# ATA5700M322 device description
Architecture: AVR8; Family: megaAVR
Registers are 8-bit, access not given, no defined reset value unless marked. A register's access mark holds for its fields unless they carry their own. Offsets are from the block's base; [hi:lo] are bit positions; {n}, {i} and the like mark numbered series.

## LF_RSSI
Instances: LF_RSSI 0x00
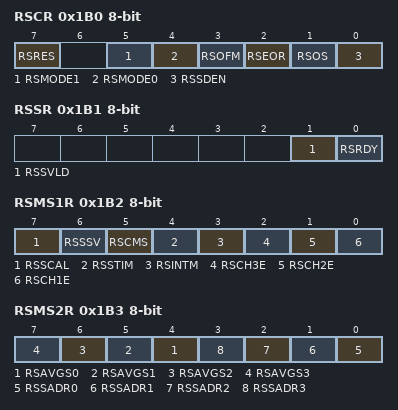
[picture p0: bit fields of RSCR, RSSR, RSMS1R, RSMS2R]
0x1B0 RSCR — RSSI Control Register
  [7] RSRES — RSSI Reset Bit
  [5] RSMODE1 — RSSI Mode Bit 1
  [4] RSMODE0 — RSSI Mode Bit 0
  [3] RSOFM — RSSI Operation Flag Mask Bit
  [2] RSEOR — RSSI End Operation Request Bit
  [1] RSOS — RSSI Operation Start Bit
  [0] RSSDEN — RSSI Sign Detection Enable Bit
0x1B1 RSSR — RSSI Status Register
  [1] RSSVLD — RSSI Sample Valid Bit
  [0] RSRDY — RSSI Ready Bit
0x1B2 RSMS1R — RSSI Measurement Setting 1 Register
  [7] RSSCAL — RSSI Set Calibration Bit
  [6] RSSSV — RSSI Show Sample Value Bit
  [5] RSCMS — RSSI Current Mode Select Bit
  [4] RSSTIM — RSSI Stimulus Bit
  [3] RSINTM — RSSI internal Measurement Bit
  [2] RSCH3E — RSSI Channel 3 Enable Bit
  [1] RSCH2E — RSSI Channel 2 Enable Bit
  [0] RSCH1E — RSSI Channel 1 Enable Bit
0x1B3 RSMS2R — RSSI Measurement Setting 2 Register
  [n+4] RSAVGS{n} (n=0..3) — RSSI Average Select Bit {n}
  [n] RSSADR{n} (n=0..3) — RSSI Sample Address Bit {n}
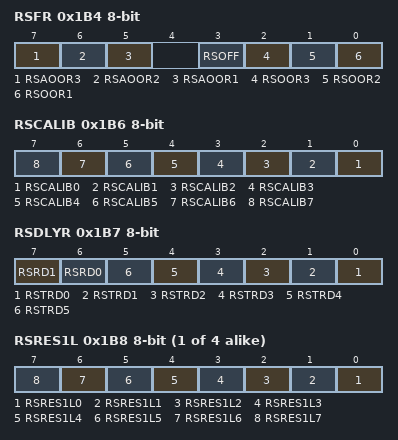
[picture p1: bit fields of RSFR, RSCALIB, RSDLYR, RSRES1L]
0x1B4 RSFR — RSSI Flag Register
  [7] RSAOOR3 — RSSI Averaging Out of Range Channel 3 Bit
  [6] RSAOOR2 — RSSI Averaging Out of Range Channel 2 Bit
  [5] RSAOOR1 — RSSI Averaging Out of Range Channel 1 Bit
  [3] RSOFF — RSSI Operation Finish Flag Bit
  [2] RSOOR3 — RSSI Out of Range Channel 3 Bit
  [1] RSOOR2 — RSSI Out of Range Channel 2 Bit
  [0] RSOOR1 — RSSI Out of Range Channel 1 Bit
0x1B6 RSCALIB — RSSI Calibration Register
  [n] RSCALIB{n} (n=0..7) — RSSI Calibration Bit {n}
0x1B7 RSDLYR — RSSI Delay Register
  [7] RSRD1 — RSSI Range Delay Bit 1
  [6] RSRD0 — RSSI Range Delay Bit 0
  [n] RSTRD{n} (n=0..5) — RSSI Tracking Delay Bit {n}
{0x1B6+2i} RSRES{i}L (i=1..4) — RSSI Result {i} Low Byte Register
  [n] RSRES{i}L{n} (n=0..7) — RSSI Result {i} Low Byte Bit {n}
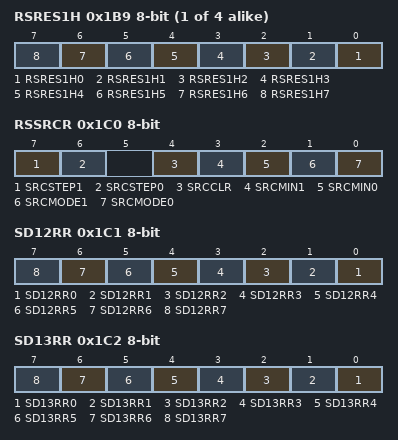
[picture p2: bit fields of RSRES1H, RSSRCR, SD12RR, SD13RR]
{0x1B7+2i} RSRES{i}H (i=1..4) — RSSI Result {i} High Byte Register
  [n] RSRES{i}H{n} (n=0..7) — RSSI Result {i} High Byte Bit {n}
0x1C0 RSSRCR — RSSI SRC Calibration Register
  [7] SRCSTEP1 — RSSI SRC Step Bit 1
  [6] SRCSTEP0 — RSSI SRC Step Bit 0
  [4] SRCCLR — RSSI SRC Clear Bit
  [3] SRCMIN1 — RSSI SRC Minimum Value Bit 1
  [2] SRCMIN0 — RSSI SRC Minimum Value Bit 0
  [1] SRCMODE1 — RSSI SRC Calibration Mode Bit 1
  [0] SRCMODE0 — RSSI SRC Calibration Mode Bit 0
0x1C1 SD12RR — Sign Detection Channel 1 vs 2 Result Register
  [n] SD12RR{n} (n=0..7) — Sign Detection Channel 1 vs 2 Result Bit {n}
0x1C2 SD13RR — Sign Detection Channel 1 vs 3 Result Register
  [n] SD13RR{n} (n=0..7) — Sign Detection Channel 1 vs 3 Result Bit {n}
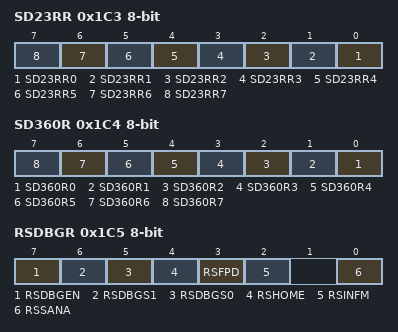
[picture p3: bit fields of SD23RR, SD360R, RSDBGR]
0x1C3 SD23RR — Sign Detection Channel 2 vs 3 Result Register
  [n] SD23RR{n} (n=0..7) — Sign Detection Channel 2 vs 3 Result Bit {n}
0x1C4 SD360R — Sign Detection 360 Degree Result Register
  [n] SD360R{n} (n=0..7) — Sign Detection 360 Degree Result Bit {n}
0x1C5 RSDBGR — RSSI Debug Register
  [7] RSDBGEN — RSSI Debug Enable Bit
  [6] RSDBGS1 — RSSI Debug Select Bit 1
  [5] RSDBGS0 — RSSI Debug Select Bit 0
  [4] RSHOME — RSSI Hold Measurement Bit
  [3] RSFPD — RSSI Fix Pre-Divider Bit
  [2] RSINFM — RSSI Infinity Measurement Bit
  [0] RSSANA — RSSI Set Analog Bit

## LF_TIMER
Instances: LF_TIMER 0x00
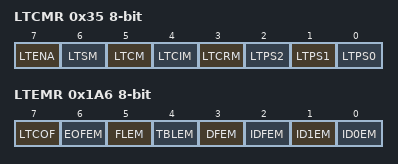
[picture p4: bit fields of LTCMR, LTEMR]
0x35 LTCMR — LF Timer Control Mode Register
  [7] LTENA — LF Timer Enable
  [6] LTSM — LF Timer Start Mode
  [5] LTCM — LF Timer Continuous Mode
  [4] LTCIM — LF Timer Compare Interrupt Mask
  [3] LTCRM — LF Timer Compare Reset Mask
  [2] LTPS2 — LF Timer Prescaler Select bit 2
  [1] LTPS1 — LF Timer Prescaler Select bit 1
  [0] LTPS0 — LF Timer Prescaler Select bit 0
0x1A1 LTCOR — LF Timer Compare Register
0x1A6 LTEMR — LF Timer Event Mask Register
  [7] LTCOF — LF Timer Compare Flag
  [6] EOFEM — End OF telegram Event Mask
  [5] FLEM — Fill Level reached Event Mask
  [4] TBLEM — Telegram Bit Length reached Event Mask
  [3] DFEM — Data Frame end reached Event Mask
  [2] IDFEM — Identifier Frame Event Mask
  [1] ID1EM — ID1 Event Mask
  [0] ID0EM — ID0 Event Mask
